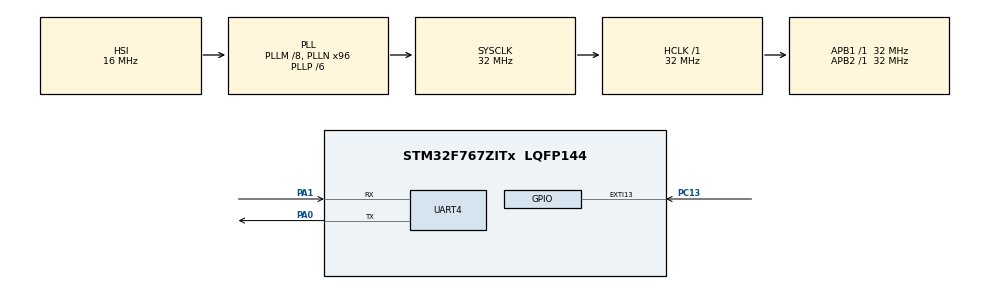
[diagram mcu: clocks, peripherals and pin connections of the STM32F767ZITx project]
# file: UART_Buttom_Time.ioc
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Mcu.Family=STM32F7
VP_TIM5_VS_ClockSourceINT.Mode=Internal
RCC.CortexFreq_Value=32000000
PC13.Signal=GPXTI13
PA0/WKUP.Signal=UART4_TX
RCC.SYSCLKSource=RCC_SYSCLKSOURCE_PLLCLK
TIM5.ClockDivision=TIM_CLOCKDIVISION_DIV1
TIM5.AutoReloadPreload=TIM_AUTORELOAD_PRELOAD_DISABLE
ProjectManager.StackSize=0x400
ProjectManager.TargetToolchain=STM32CubeIDE
NVIC.TIM5_IRQn=true\:1\:0\:true\:false\:true\:true\:true
RCC.HCLKFreq_Value=32000000
RCC.APB2TimFreq_Value=32000000
RCC.USBFreq_Value=96000000
RCC.LSE_VALUE=32768
PA1.Signal=UART4_RX
RCC.AHBFreq_Value=32000000
PA0/WKUP.Mode=Asynchronous
NVIC.EXTI15_10_IRQn=true\:0\:0\:false\:false\:true\:true\:true
RCC.HSE_VALUE=25000000
board=custom
RCC.VCOOutputFreq_Value=192000000
RCC.APB2Freq_Value=32000000
PA1.Mode=Asynchronous
Mcu.Name=STM32F767ZITx
RCC.SYSCLKFreq_VALUE=32000000
Mcu.Package=LQFP144
TIM5.Prescaler=32000-1
ProjectManager.HeapSize=0x200
RCC.HSI_VALUE=16000000
RCC.PLLP=RCC_PLLP_DIV6
NVIC.PriorityGroup=NVIC_PRIORITYGROUP_4
RCC.PLLM=8
RCC.PLLN=96
RCC.APB1TimFreq_Value=32000000
TIM5.Period=4000000000
RCC.APB1Freq_Value=32000000

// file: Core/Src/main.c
/* USER CODE BEGIN Header */
/**
  ******************************************************************************
  * @file           : main.c
  * @brief          : Main program body
  ******************************************************************************
  * @attention
  *
  * <h2><center>&copy; Copyright (c) 2021 STMicroelectronics.
  * All rights reserved.</center></h2>
  *
  * This software component is licensed by ST under BSD 3-Clause license,
  * the "License"; You may not use this file except in compliance with the
  * License. You may obtain a copy of the License at:
  *                        opensource.org/licenses/BSD-3-Clause
  *
  ******************************************************************************
  */
/* USER CODE END Header */
#include "main.h"

/* USER CODE BEGIN Includes */
#include <string.h>
#include <stdio.h>

/* USER CODE END Includes */

/* USER CODE BEGIN PD */
uint32_t time;
uint8_t temp = 0;

/* USER CODE END PD */

TIM_HandleTypeDef htim5;

UART_HandleTypeDef huart4;

void SystemClock_Config(void);
static void MX_GPIO_Init(void);
static void MX_TIM5_Init(void);
static void MX_UART4_Init(void);

int main(void)
{

  /* MCU Configuration--------------------------------------------------------*/

  /* Reset of all peripherals, Initializes the Flash interface and the Systick. */
  HAL_Init();

  /* Configure the system clock */
  SystemClock_Config();

  /* Initialize all configured peripherals */
  MX_GPIO_Init();
  MX_TIM5_Init();
  MX_UART4_Init();

  /* Infinite loop */
  /* USER CODE BEGIN WHILE */
  while (1)
  {
	  time=__HAL_TIM_GET_COUNTER(&htim5)/1000;

	  if ((1 == HAL_GPIO_ReadPin(GPIOC, GPIO_PIN_13)) && (temp == 0))
		  	  {
				HAL_TIM_Base_Start_IT(&htim5);
				temp = 1;
		  	  }

	  if ((0 == HAL_GPIO_ReadPin(GPIOC, GPIO_PIN_13)) && (temp == 1))
		  	  {
				char buffer[20];
				sprintf(buffer," ");
				char i;
				i = sprintf(buffer,"%lu sec \n", time);
				if (time >= 1)
				{
					HAL_UART_Transmit(&huart4, (uint8_t*)buffer, i, 100);
				}
					HAL_TIM_Base_Stop_IT(&htim5);
					__HAL_TIM_SET_COUNTER(&htim5,0);
					time = 0;
					temp = 0;

	  }

    /* USER CODE END WHILE */

  }
}

void SystemClock_Config(void)
{
  RCC_OscInitTypeDef RCC_OscInitStruct = {0};
  RCC_ClkInitTypeDef RCC_ClkInitStruct = {0};
  RCC_PeriphCLKInitTypeDef PeriphClkInitStruct = {0};

  /** Configure the main internal regulator output voltage
  */
  __HAL_RCC_PWR_CLK_ENABLE();
  __HAL_PWR_VOLTAGESCALING_CONFIG(PWR_REGULATOR_VOLTAGE_SCALE3);
  /** Initializes the RCC Oscillators according to the specified parameters
  * in the RCC_OscInitTypeDef structure.
  */
  RCC_OscInitStruct.OscillatorType = RCC_OSCILLATORTYPE_HSI;
  RCC_OscInitStruct.HSIState = RCC_HSI_ON;
  RCC_OscInitStruct.HSICalibrationValue = RCC_HSICALIBRATION_DEFAULT;
  RCC_OscInitStruct.PLL.PLLState = RCC_PLL_ON;
  RCC_OscInitStruct.PLL.PLLSource = RCC_PLLSOURCE_HSI;
  RCC_OscInitStruct.PLL.PLLM = 8;
  RCC_OscInitStruct.PLL.PLLN = 96;
  RCC_OscInitStruct.PLL.PLLP = RCC_PLLP_DIV6;
  RCC_OscInitStruct.PLL.PLLQ = 2;
  if (HAL_RCC_OscConfig(&RCC_OscInitStruct) != HAL_OK)
  {
    Error_Handler();
  }
  /** Initializes the CPU, AHB and APB buses clocks
  */
  RCC_ClkInitStruct.ClockType = RCC_CLOCKTYPE_HCLK|RCC_CLOCKTYPE_SYSCLK
                              |RCC_CLOCKTYPE_PCLK1|RCC_CLOCKTYPE_PCLK2;
  RCC_ClkInitStruct.SYSCLKSource = RCC_SYSCLKSOURCE_PLLCLK;
  RCC_ClkInitStruct.AHBCLKDivider = RCC_SYSCLK_DIV1;
  RCC_ClkInitStruct.APB1CLKDivider = RCC_HCLK_DIV1;
  RCC_ClkInitStruct.APB2CLKDivider = RCC_HCLK_DIV1;

  if (HAL_RCC_ClockConfig(&RCC_ClkInitStruct, FLASH_LATENCY_1) != HAL_OK)
  {
    Error_Handler();
  }
  PeriphClkInitStruct.PeriphClockSelection = RCC_PERIPHCLK_UART4;
  PeriphClkInitStruct.Uart4ClockSelection = RCC_UART4CLKSOURCE_PCLK1;
  if (HAL_RCCEx_PeriphCLKConfig(&PeriphClkInitStruct) != HAL_OK)
  {
    Error_Handler();
  }
}

static void MX_TIM5_Init(void)
{

  TIM_ClockConfigTypeDef sClockSourceConfig = {0};
  TIM_MasterConfigTypeDef sMasterConfig = {0};

  htim5.Instance = TIM5;
  htim5.Init.Prescaler = 32000-1;
  htim5.Init.CounterMode = TIM_COUNTERMODE_UP;
  htim5.Init.Period = 4000000000;
  htim5.Init.ClockDivision = TIM_CLOCKDIVISION_DIV1;
  htim5.Init.AutoReloadPreload = TIM_AUTORELOAD_PRELOAD_DISABLE;
  if (HAL_TIM_Base_Init(&htim5) != HAL_OK)
  {
    Error_Handler();
  }
  sClockSourceConfig.ClockSource = TIM_CLOCKSOURCE_INTERNAL;
  if (HAL_TIM_ConfigClockSource(&htim5, &sClockSourceConfig) != HAL_OK)
  {
    Error_Handler();
  }
  sMasterConfig.MasterOutputTrigger = TIM_TRGO_RESET;
  sMasterConfig.MasterSlaveMode = TIM_MASTERSLAVEMODE_DISABLE;
  if (HAL_TIMEx_MasterConfigSynchronization(&htim5, &sMasterConfig) != HAL_OK)
  {
    Error_Handler();
  }

}

static void MX_UART4_Init(void)
{

  huart4.Instance = UART4;
  huart4.Init.BaudRate = 115200;
  huart4.Init.WordLength = UART_WORDLENGTH_8B;
  huart4.Init.StopBits = UART_STOPBITS_1;
  huart4.Init.Parity = UART_PARITY_NONE;
  huart4.Init.Mode = UART_MODE_TX_RX;
  huart4.Init.HwFlowCtl = UART_HWCONTROL_NONE;
  huart4.Init.OverSampling = UART_OVERSAMPLING_16;
  huart4.Init.OneBitSampling = UART_ONE_BIT_SAMPLE_DISABLE;
  huart4.AdvancedInit.AdvFeatureInit = UART_ADVFEATURE_NO_INIT;
  if (HAL_UART_Init(&huart4) != HAL_OK)
  {
    Error_Handler();
  }

}

static void MX_GPIO_Init(void)
{
  GPIO_InitTypeDef GPIO_InitStruct = {0};

  /* GPIO Ports Clock Enable */
  __HAL_RCC_GPIOC_CLK_ENABLE();
  __HAL_RCC_GPIOA_CLK_ENABLE();

  /*Configure GPIO pin : PC13 */
  GPIO_InitStruct.Pin = GPIO_PIN_13;
  GPIO_InitStruct.Mode = GPIO_MODE_IT_RISING;
  GPIO_InitStruct.Pull = GPIO_NOPULL;
  HAL_GPIO_Init(GPIOC, &GPIO_InitStruct);

  /* EXTI interrupt init*/
  HAL_NVIC_SetPriority(EXTI15_10_IRQn, 0, 0);
  HAL_NVIC_EnableIRQ(EXTI15_10_IRQn);

}

void Error_Handler(void)
{
  __disable_irq();
  while (1)
  {
  }
}

/************************ (C) COPYRIGHT STMicroelectronics *****END OF FILE****/
